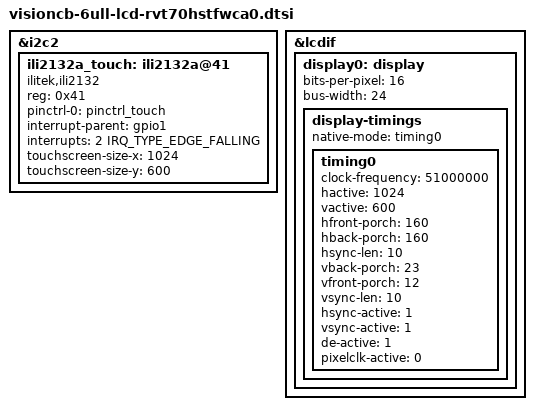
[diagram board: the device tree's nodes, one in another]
// SPDX-License-Identifier: GPL-2.0-or-later
/*
 * Copyright (C) 2020-2023 SoMLabs
 */

&i2c2 {
        ili2132a_touch: ili2132a@41 {
                status = "okay";
                compatible = "ilitek,ili2132";
                reg = <0x41>;
                pinctrl-names = "default";
                pinctrl-0 = <&pinctrl_touch>;
                interrupt-parent = <&gpio1>;
                interrupts = <2 IRQ_TYPE_EDGE_FALLING>;
                touchscreen-size-x = <1024>;
                touchscreen-size-y = <600>;
        };
};

&lcdif {
        display0: display {
                bits-per-pixel = <16>;
                bus-width = <24>;

                display-timings {
                        native-mode = <&timing0>;
                        timing0: timing0 {
                                clock-frequency = <51000000>;
                                hactive = <1024>;
                                vactive = <600>;
                                hfront-porch = <160>;
                                hback-porch = <160>;
                                hsync-len = <10>;
                                vback-porch = <23>;
                                vfront-porch = <12>;
                                vsync-len = <10>;

                                hsync-active = <1>;
                                vsync-active = <1>;
                                de-active = <1>;
                                pixelclk-active = <0>;
                        };
                };
        };
};
